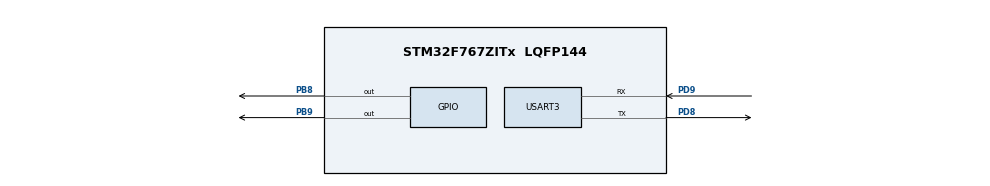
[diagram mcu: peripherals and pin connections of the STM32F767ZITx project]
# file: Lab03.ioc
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Mcu.Family=STM32F7
Mcu.Name=STM32F767ZITx
Mcu.Package=LQFP144
NVIC.PriorityGroup=NVIC_PRIORITYGROUP_4
PB8.Signal=GPIO_Output
PB9.Signal=GPIO_Output
PD8.Mode=Asynchronous
PD8.Signal=USART3_TX
PD9.Mode=Asynchronous
PD9.Signal=USART3_RX
ProjectManager.HeapSize=0x200
ProjectManager.StackSize=0x400
ProjectManager.TargetToolchain=STM32CubeIDE
RCC.HSE_VALUE=25000000
RCC.HSI_VALUE=16000000
RCC.LSE_VALUE=32768
RCC.USBFreq_Value=96000000
RCC.VCOOutputFreq_Value=192000000
USART3.VirtualMode-Asynchronous=VM_ASYNC
board=custom

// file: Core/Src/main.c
/* USER CODE BEGIN Header */
/**
  ******************************************************************************
  * @file           : main.c
  * @brief          : Main program body
  ******************************************************************************
  * @attention
  *
  * Copyright (c) 2023 STMicroelectronics.
  * All rights reserved.
  *
  * This software is licensed under terms that can be found in the LICENSE file
  * in the root directory of this software component.
  * If no LICENSE file comes with this software, it is provided AS-IS.
  *
  ******************************************************************************
  */
/* USER CODE END Header */
#include "main.h"
#include "usart.h"
#include "gpio.h"
#include "string.h"
#include "stdbool.h"

/* USER CODE BEGIN PV */
	int isQuit = 0;
/* USER CODE END PV */

void SystemClock_Config(void);

int main(void)
{

  /* MCU Configuration--------------------------------------------------------*/

  /* Reset of all peripherals, Initializes the Flash interface and the Systick. */
  HAL_Init();

  /* Configure the system clock */
  SystemClock_Config();

  /* Initialize all configured peripherals */
  MX_GPIO_Init();
  MX_USART3_UART_Init();

  /* Infinite loop */
  while (1)
  {
	  int isQuit2 = 0;
	  while(!isQuit2){
		  MenuCommand(&isQuit2);
	  }
  }
}

void MenuCommand(int *isQuit) {

	char introCommand[] =
			"Display Blinking LED PRESS (1, 2)\r\nDisplay Group Members PRESS m \r\nQuit PRESS q \r\n";

	 PrintOut(introCommand);

	while (!*isQuit) {
		char command;
		UserInput(&command);
		CheckCommand(command, &isQuit);
	}

}

void UserInput(char *inputChar) {
	PrintOut("\tInput =>");

	char input;
	while(__HAL_UART_GET_FLAG(&huart3, UART_FLAG_RXNE) == RESET){}
	HAL_UART_Receive(&huart3, (uint8_t*) &input, 1, 1000);
	Delay();

	PrintOutLine(&input);
	*inputChar = input;
}

void CheckCommand(char inputChar, int *isQuit) {
	char memberText[] =
			"64010989\n\rAttaphon Plianprasert\n\r64011113\n\rNatchanon Bunyachawaset\n\r641264\n\rVoraphol Promwan\n\r";

	if (inputChar == '1') {
//		BlinkLed(1);
	}
	else if (inputChar == '2') {
//		BlinkLed(2);
	}
	else if (inputChar == 'm') {
		PrintOut(memberText);
	}
	else if (inputChar == 'q') {
		*isQuit = 1;
		PrintOutLine("QUIT");
	}
	else {
		PrintOutLine("Unknown Command");
	}

}

void BlinkLed(int ledNum){
	uint16_t pin = ledNum == 1? GPIO_PIN_8 : GPIO_PIN_9;
//	for (int n = 0; n < 3; n++) {
//		HAL_GPIO_WritePin(GPIOB, pin, GPIO_PIN_RESET);
//		HAL_Delay(300);
//		HAL_GPIO_WritePin(GPIOB, pin, GPIO_PIN_SET);
//		HAL_delay(300);
//	}
}

void PrintOut(char text[]){
	while(__HAL_UART_GET_FLAG(&huart3, UART_FLAG_TC) == RESET){}
	HAL_UART_Transmit(&huart3, (uint8_t*) text, strlen(text), 1000);
	Delay();
}

void PrintOutLine(char text[]){
	PrintOut(text);
	PrintOut("\n\r");
}

void Delay() {
	HAL_Delay(10);
}

void SystemClock_Config(void)
{
  RCC_OscInitTypeDef RCC_OscInitStruct = {0};
  RCC_ClkInitTypeDef RCC_ClkInitStruct = {0};

  /** Configure the main internal regulator output voltage
  */
  __HAL_RCC_PWR_CLK_ENABLE();
  __HAL_PWR_VOLTAGESCALING_CONFIG(PWR_REGULATOR_VOLTAGE_SCALE3);

  /** Initializes the RCC Oscillators according to the specified parameters
  * in the RCC_OscInitTypeDef structure.
  */
  RCC_OscInitStruct.OscillatorType = RCC_OSCILLATORTYPE_HSI;
  RCC_OscInitStruct.HSIState = RCC_HSI_ON;
  RCC_OscInitStruct.HSICalibrationValue = RCC_HSICALIBRATION_DEFAULT;
  RCC_OscInitStruct.PLL.PLLState = RCC_PLL_NONE;
  if (HAL_RCC_OscConfig(&RCC_OscInitStruct) != HAL_OK)
  {
    Error_Handler();
  }

  /** Initializes the CPU, AHB and APB buses clocks
  */
  RCC_ClkInitStruct.ClockType = RCC_CLOCKTYPE_HCLK|RCC_CLOCKTYPE_SYSCLK
                              |RCC_CLOCKTYPE_PCLK1|RCC_CLOCKTYPE_PCLK2;
  RCC_ClkInitStruct.SYSCLKSource = RCC_SYSCLKSOURCE_HSI;
  RCC_ClkInitStruct.AHBCLKDivider = RCC_SYSCLK_DIV1;
  RCC_ClkInitStruct.APB1CLKDivider = RCC_HCLK_DIV1;
  RCC_ClkInitStruct.APB2CLKDivider = RCC_HCLK_DIV1;

  if (HAL_RCC_ClockConfig(&RCC_ClkInitStruct, FLASH_LATENCY_0) != HAL_OK)
  {
    Error_Handler();
  }
}

void Error_Handler(void)
{
  __disable_irq();
  while (1)
  {
  }
}
